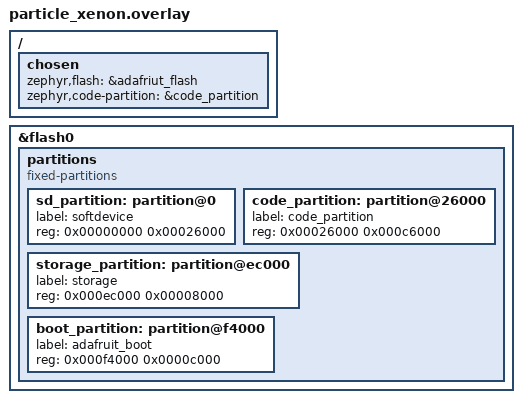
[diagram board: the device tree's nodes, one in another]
/*
 * Copyright (c) 2020-2021 The ZMK Contributors
 *
 * SPDX-License-Identifier: MIT
 */

// remove duplicated partition from zephyr particle configuration
/delete-node/ &storage_partition;
/delete-node/ &boot_partition;

adafriut_flash: &flash0 {
	/*
	 * For more information, see:
	 * https://docs.zephyrproject.org/latest/reference/storage/flash_map/flash_map.html
	 */
	partitions {
		compatible = "fixed-partitions";
		#address-cells = <1>;
		#size-cells = <1>;

		sd_partition: partition@0 {
			label = "softdevice";
			reg = <0x00000000 0x00026000>;
		};
		code_partition: partition@26000 {
			label = "code_partition";
			reg = <0x00026000 0x000c6000>;
		};

		/*
		* The flash starting at 0x000ec000 and ending at
		* 0x000f3fff is reserved for use by the application.
		*/

		/*
		* Storage partition will be used by FCB/LittleFS/NVS
		* if enabled.
		*/
		storage_partition: partition@ec000 {
			label = "storage";
			reg = <0x000ec000 0x00008000>;
		};

		boot_partition: partition@f4000 {
			label = "adafruit_boot";
			reg = <0x000f4000 0x0000c000>;
		};

	};
};

/ {
	chosen {
		zephyr,flash = &adafriut_flash;
		zephyr,code-partition = &code_partition;
	};
};
